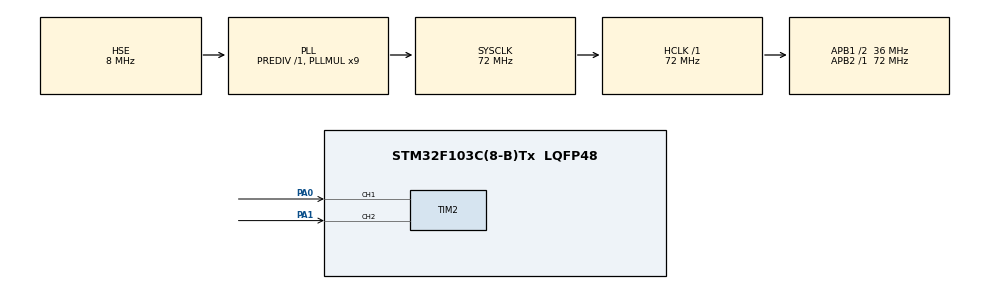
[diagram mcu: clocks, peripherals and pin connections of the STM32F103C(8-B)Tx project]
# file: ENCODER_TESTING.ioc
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Mcu.Family=STM32F1
Mcu.Name=STM32F103C(8-B)Tx
Mcu.Package=LQFP48
NVIC.PriorityGroup=NVIC_PRIORITYGROUP_4
NVIC.TIM2_IRQn=true\:0\:0\:false\:false\:true\:true\:true\:true
PA0-WKUP.Signal=S_TIM2_CH1_ETR
PA1.Signal=S_TIM2_CH2
PA13.Mode=Serial_Wire
PA13.Signal=SYS_JTMS-SWDIO
PA14.Mode=Serial_Wire
PA14.Signal=SYS_JTCK-SWCLK
PD0-OSC_IN.Mode=HSE-External-Oscillator
PD0-OSC_IN.Signal=RCC_OSC_IN
PD1-OSC_OUT.Mode=HSE-External-Oscillator
PD1-OSC_OUT.Signal=RCC_OSC_OUT
ProjectManager.HeapSize=0x200
ProjectManager.StackSize=0x400
ProjectManager.TargetToolchain=STM32CubeIDE
RCC.AHBFreq_Value=72000000
RCC.APB1CLKDivider=RCC_HCLK_DIV2
RCC.APB1Freq_Value=36000000
RCC.APB1TimFreq_Value=72000000
RCC.APB2Freq_Value=72000000
RCC.APB2TimFreq_Value=72000000
RCC.HCLKFreq_Value=72000000
RCC.PLLMUL=RCC_PLL_MUL9
RCC.PLLSourceVirtual=RCC_PLLSOURCE_HSE
RCC.SYSCLKFreq_VALUE=72000000
RCC.SYSCLKSource=RCC_SYSCLKSOURCE_PLLCLK
RCC.USBFreq_Value=72000000
SH.S_TIM2_CH1_ETR.0=TIM2_CH1,Encoder_Interface
SH.S_TIM2_CH2.0=TIM2_CH2,Encoder_Interface
TIM2.AutoReloadPreload=TIM_AUTORELOAD_PRELOAD_ENABLE
TIM2.EncoderMode=TIM_ENCODERMODE_TI12
TIM2.IC1Filter=0
board=custom

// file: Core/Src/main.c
/* USER CODE BEGIN Header */
/**
  ******************************************************************************
  * @file           : main.c
  * @brief          : Main program body
  ******************************************************************************
  * @attention
  *
  * Copyright (c) 2024 STMicroelectronics.
  * All rights reserved.
  *
  * This software is licensed under terms that can be found in the LICENSE file
  * in the root directory of this software component.
  * If no LICENSE file comes with this software, it is provided AS-IS.
  *
  ******************************************************************************
  */
/* USER CODE END Header */
#include "main.h"

TIM_HandleTypeDef htim2;

/* USER CODE BEGIN PV */
//int cnt;
//

//uint_16 cnt;

/* USER CODE END PV */

void SystemClock_Config(void);
static void MX_GPIO_Init(void);
static void MX_TIM2_Init(void);

/* USER CODE BEGIN 0 */
uint32_t counter = 0;
uint32_t encoder_count = 0;

uint16_t count = 0;

uint16_t position;

uint32_t speed = 0;
uint32_t last_encoder_count = 0;

/* USER CODE END 0 */

int main(void)
{

  /* MCU Configuration--------------------------------------------------------*/

  /* Reset of all peripherals, Initializes the Flash interface and the Systick. */
  HAL_Init();

  /* Configure the system clock */
  SystemClock_Config();

  /* Initialize all configured peripherals */
  MX_GPIO_Init();
  MX_TIM2_Init();
  /* USER CODE BEGIN 2 */
  HAL_TIM_Encoder_Start(&htim2, TIM_CHANNEL_ALL);

  /* USER CODE END 2 */

  /* Infinite loop */
  while (1)
  {

    /* USER CODE BEGIN 3 */
	  count = TIM2->CNT;
	  uint32_t counter = __HAL_TIM_GET_COUNTER(&htim2);
	  count = (int16_t) counter;
	  position = __HAL_TIM_GET_COUNTER(&htim2)/4;
  }
  /* USER CODE END 3 */
}

void SystemClock_Config(void)
{
  RCC_OscInitTypeDef RCC_OscInitStruct = {0};
  RCC_ClkInitTypeDef RCC_ClkInitStruct = {0};

  /** Initializes the RCC Oscillators according to the specified parameters
  * in the RCC_OscInitTypeDef structure.
  */
  RCC_OscInitStruct.OscillatorType = RCC_OSCILLATORTYPE_HSE;
  RCC_OscInitStruct.HSEState = RCC_HSE_ON;
  RCC_OscInitStruct.HSEPredivValue = RCC_HSE_PREDIV_DIV1;
  RCC_OscInitStruct.HSIState = RCC_HSI_ON;
  RCC_OscInitStruct.PLL.PLLState = RCC_PLL_ON;
  RCC_OscInitStruct.PLL.PLLSource = RCC_PLLSOURCE_HSE;
  RCC_OscInitStruct.PLL.PLLMUL = RCC_PLL_MUL9;
  if (HAL_RCC_OscConfig(&RCC_OscInitStruct) != HAL_OK)
  {
    Error_Handler();
  }

  /** Initializes the CPU, AHB and APB buses clocks
  */
  RCC_ClkInitStruct.ClockType = RCC_CLOCKTYPE_HCLK|RCC_CLOCKTYPE_SYSCLK
                              |RCC_CLOCKTYPE_PCLK1|RCC_CLOCKTYPE_PCLK2;
  RCC_ClkInitStruct.SYSCLKSource = RCC_SYSCLKSOURCE_PLLCLK;
  RCC_ClkInitStruct.AHBCLKDivider = RCC_SYSCLK_DIV1;
  RCC_ClkInitStruct.APB1CLKDivider = RCC_HCLK_DIV2;
  RCC_ClkInitStruct.APB2CLKDivider = RCC_HCLK_DIV1;

  if (HAL_RCC_ClockConfig(&RCC_ClkInitStruct, FLASH_LATENCY_2) != HAL_OK)
  {
    Error_Handler();
  }
}

static void MX_TIM2_Init(void)
{

  TIM_Encoder_InitTypeDef sConfig = {0};
  TIM_MasterConfigTypeDef sMasterConfig = {0};

  htim2.Instance = TIM2;
  htim2.Init.Prescaler = 0;
  htim2.Init.CounterMode = TIM_COUNTERMODE_UP;
  htim2.Init.Period = 65535;
  htim2.Init.ClockDivision = TIM_CLOCKDIVISION_DIV1;
  htim2.Init.AutoReloadPreload = TIM_AUTORELOAD_PRELOAD_ENABLE;
  sConfig.EncoderMode = TIM_ENCODERMODE_TI12;
  sConfig.IC1Polarity = TIM_ICPOLARITY_RISING;
  sConfig.IC1Selection = TIM_ICSELECTION_DIRECTTI;
  sConfig.IC1Prescaler = TIM_ICPSC_DIV1;
  sConfig.IC1Filter = 0;
  sConfig.IC2Polarity = TIM_ICPOLARITY_RISING;
  sConfig.IC2Selection = TIM_ICSELECTION_DIRECTTI;
  sConfig.IC2Prescaler = TIM_ICPSC_DIV1;
  sConfig.IC2Filter = 0;
  if (HAL_TIM_Encoder_Init(&htim2, &sConfig) != HAL_OK)
  {
    Error_Handler();
  }
  sMasterConfig.MasterOutputTrigger = TIM_TRGO_RESET;
  sMasterConfig.MasterSlaveMode = TIM_MASTERSLAVEMODE_DISABLE;
  if (HAL_TIMEx_MasterConfigSynchronization(&htim2, &sMasterConfig) != HAL_OK)
  {
    Error_Handler();
  }

}

static void MX_GPIO_Init(void)
{

  /* GPIO Ports Clock Enable */
  __HAL_RCC_GPIOD_CLK_ENABLE();
  __HAL_RCC_GPIOA_CLK_ENABLE();

}

void Error_Handler(void)
{
  __disable_irq();
  while (1)
  {
  }
}
